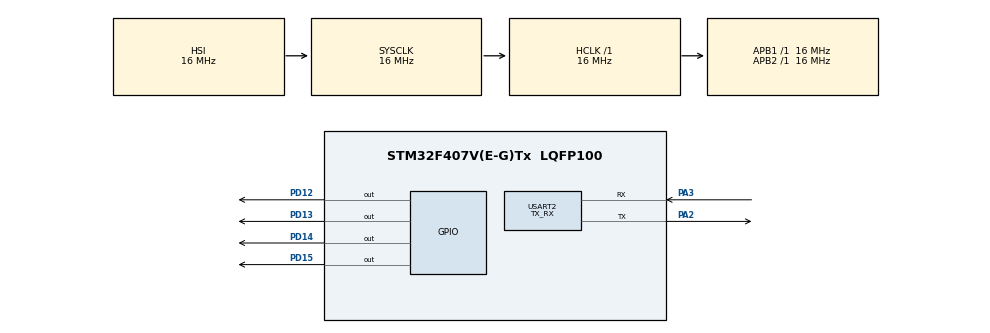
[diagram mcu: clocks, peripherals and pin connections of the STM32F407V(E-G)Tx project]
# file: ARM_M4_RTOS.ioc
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FREERTOS.Tasks01=led_blink,14,128,led_blink_func,Default,NULL,Dynamic,NULL,NULL;usart2_tx,40,128,usart2_tx_func,Default,NULL,Dynamic,NULL,NULL;usart2_rx,41,128,usart2_rx_func,Default,NULL,Dynamic,NULL,NULL
FREERTOS.configUSE_NEWLIB_REENTRANT=1
Mcu.Family=STM32F4
Mcu.Name=STM32F407V(E-G)Tx
Mcu.Package=LQFP100
NVIC.PriorityGroup=NVIC_PRIORITYGROUP_4
NVIC.TIM4_IRQn=true\:15\:0\:false\:false\:true\:false\:false\:true\:true
NVIC.TimeBase=TIM4_IRQn
NVIC.TimeBaseIP=TIM4
PA13.Mode=Serial_Wire
PA13.Signal=SYS_JTMS-SWDIO
PA14.Mode=Serial_Wire
PA14.Signal=SYS_JTCK-SWCLK
PA2.Mode=Asynchronous
PA2.Signal=USART2_TX
PA3.Mode=Asynchronous
PA3.Signal=USART2_RX
PD12.Signal=GPIO_Output
PD13.Signal=GPIO_Output
PD14.Signal=GPIO_Output
PD15.Signal=GPIO_Output
PH0-OSC_IN.Mode=HSE-External-Oscillator
PH0-OSC_IN.Signal=RCC_OSC_IN
PH1-OSC_OUT.Mode=HSE-External-Oscillator
PH1-OSC_OUT.Signal=RCC_OSC_OUT
ProjectManager.HeapSize=0x200
ProjectManager.StackSize=0x400
ProjectManager.TargetToolchain=STM32CubeIDE
RCC.48MHZClocksFreq_Value=96000000
RCC.AHBFreq_Value=16000000
RCC.APB1Freq_Value=16000000
RCC.APB1TimFreq_Value=16000000
RCC.APB2Freq_Value=16000000
RCC.APB2TimFreq_Value=16000000
RCC.CortexFreq_Value=16000000
RCC.HCLKFreq_Value=16000000
RCC.HSE_VALUE=25000000
RCC.HSI_VALUE=16000000
RCC.LSE_VALUE=32768
RCC.PLLM=8
RCC.SYSCLKFreq_VALUE=16000000
RCC.VCOOutputFreq_Value=384000000
USART2.Mode=MODE_TX_RX
USART2.VirtualMode=VM_ASYNC
VP_FREERTOS_VS_CMSIS_V2.Mode=CMSIS_V2
VP_SYS_VS_tim4.Mode=TIM4
board=custom

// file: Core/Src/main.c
/* USER CODE BEGIN Header */
/**
  ******************************************************************************
  * @file           : main.c
  * @brief          : Main program body
  ******************************************************************************
  * @attention
  *
  * Copyright (c) 2026 STMicroelectronics.
  * All rights reserved.
  *
  * This software is licensed under terms that can be found in the LICENSE file
  * in the root directory of this software component.
  * If no LICENSE file comes with this software, it is provided AS-IS.0
  *
  ******************************************************************************
  */
/* USER CODE END Header */
#include "main.h"
#include "cmsis_os.h"
#include "usart.h"
#include "gpio.h"
#include "bl_jump2_appl.h"

void SystemClock_Config(void);
void MX_FREERTOS_Init(void);

/* Flash section non-optimizable defined for allocate the appl key to be validate */
__attribute__((section(".appl_header"))) const appl_header_t appl_header =
{
		.magic_number = 0xAAAACCCC,
		.crc32        = 0x0BB5A287,
		.appl_size    = 21248,
		.ota_flag     = 0,
		.checksum     = 0
};

int main(void)
{

  /* MCU Configuration--------------------------------------------------------*/

  /* Reset of all peripherals, Initializes the Flash interface and the Systick. */
  HAL_Init();

  /* USER CODE BEGIN Init */

  /* Application startup time procedures:
   * Re-fetch of vector tables's application flash region / reset handler entry point
   * Enable interrupts previously disabled by the Bootloader */
   SCB->VTOR = APPL_START_ADDR;
   __enable_irq();

  /* USER CODE END Init */

  /* Configure the system clock */
  SystemClock_Config();

  /* Initialize all configured peripherals */
  MX_GPIO_Init();
  MX_USART2_UART_Init();

  /* Init scheduler */

  osKernelInitialize();  /* Call init function for freertos objects (in cmsis_os2.c) */

  MX_FREERTOS_Init();

  /* Start scheduler */
  osKernelStart();

  /* We should never get here as control is now taken by the scheduler */

  /* Infinite loop */
  while (1)
  {

  }
}

void SystemClock_Config(void)
{
  RCC_OscInitTypeDef RCC_OscInitStruct = {0};
  RCC_ClkInitTypeDef RCC_ClkInitStruct = {0};

  /** Configure the main internal regulator output voltage
  */
  __HAL_RCC_PWR_CLK_ENABLE();
  __HAL_PWR_VOLTAGESCALING_CONFIG(PWR_REGULATOR_VOLTAGE_SCALE1);

  /** Initializes the RCC Oscillators according to the specified parameters
  * in the RCC_OscInitTypeDef structure.
  */
  RCC_OscInitStruct.OscillatorType = RCC_OSCILLATORTYPE_HSI;
  RCC_OscInitStruct.HSIState = RCC_HSI_ON;
  RCC_OscInitStruct.HSICalibrationValue = RCC_HSICALIBRATION_DEFAULT;
  RCC_OscInitStruct.PLL.PLLState = RCC_PLL_NONE;
  if (HAL_RCC_OscConfig(&RCC_OscInitStruct) != HAL_OK)
  {
    Error_Handler();
  }

  /** Initializes the CPU, AHB and APB buses clocks
  */
  RCC_ClkInitStruct.ClockType = RCC_CLOCKTYPE_HCLK|RCC_CLOCKTYPE_SYSCLK
                              |RCC_CLOCKTYPE_PCLK1|RCC_CLOCKTYPE_PCLK2;
  RCC_ClkInitStruct.SYSCLKSource = RCC_SYSCLKSOURCE_HSI;
  RCC_ClkInitStruct.AHBCLKDivider = RCC_SYSCLK_DIV1;
  RCC_ClkInitStruct.APB1CLKDivider = RCC_HCLK_DIV1;
  RCC_ClkInitStruct.APB2CLKDivider = RCC_HCLK_DIV1;

  if (HAL_RCC_ClockConfig(&RCC_ClkInitStruct, FLASH_LATENCY_0) != HAL_OK)
  {
    Error_Handler();
  }
}

void HAL_TIM_PeriodElapsedCallback(TIM_HandleTypeDef *htim)
{
  if (htim->Instance == TIM4)
  {
    HAL_IncTick();
  }
}

void Error_Handler(void)
{
  __disable_irq();
  while (1)
  {
  }
}

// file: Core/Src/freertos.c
/* USER CODE BEGIN Header */
/**
  ******************************************************************************
  * File Name          : freertos.c
  * Description        : Code for freertos applications
  ******************************************************************************
  * @attention
  *
  * Copyright (c) 2026 STMicroelectronics.
  * All rights reserved.
  *
  * This software is licensed under terms that can be found in the LICENSE file
  * in the root directory of this software component.
  * If no LICENSE file comes with this software, it is provided AS-IS.
  *
  ******************************************************************************
  */
/* USER CODE END Header */

#include "FreeRTOS.h"
#include "task.h"
#include "main.h"
#include "cmsis_os.h"

/* USER CODE BEGIN PM */
#define RXBUFFERSIZE 10
/* Exported macro ------------------------------------------------------------*/
#define COUNTOF(__BUFFER__)   (sizeof(__BUFFER__) / sizeof(*(__BUFFER__)))
/* Exported functions ------------------------------------------------------- */
/* Size of Transmission buffer */
#define TXBUFFERSIZE                      (COUNTOF(aTxBuffer) - 1)
/* Size of Reception buffer */

/* USER CODE END PM */

/* USER CODE BEGIN Variables */
uint8_t rtos_tx_buffer[] = {"JUMP to RTOS appl successful...\n"};
uint8_t rtos_rx_buffer[5];
/* USER CODE END Variables */
/* Definitions for led_blink */

osThreadId_t led_blinkHandle;
const osThreadAttr_t led_blink_attributes = {
  .name = "led_blink",
  .stack_size = 128 * 4,
  .priority = (osPriority_t) osPriorityLow6,
};
/* Definitions for usart2_tx */
osThreadId_t usart2_txHandle;
const osThreadAttr_t usart2_tx_attributes = {
  .name = "usart2_tx",
  .stack_size = 128 * 4,
  .priority = (osPriority_t) osPriorityNormal3,
};
/* Definitions for usart2_rx */
osThreadId_t usart2_rxHandle;
const osThreadAttr_t usart2_rx_attributes = {
  .name = "usart2_rx",
  .stack_size = 128 * 4,
  .priority = (osPriority_t) osPriorityHigh,
};

void led_blink_func(void *argument);
void usart2_tx_func(void *argument);
void usart2_rx_func(void *argument);

void MX_FREERTOS_Init(void); /* (MISRA C 2004 rule 8.1) */

void MX_FREERTOS_Init(void) {

  /* Create the thread(s) */
  /* creation of led_blink */
  led_blinkHandle = osThreadNew(led_blink_func, NULL, &led_blink_attributes);

  /* creation of usart2_tx */
  usart2_txHandle = osThreadNew(usart2_tx_func, NULL, &usart2_tx_attributes);

  /* creation of usart2_rx */
  //usart2_rxHandle = osThreadNew(usart2_rx_func, NULL, &usart2_rx_attributes);

}

void led_blink_func(void *argument)
{
  /* USER CODE BEGIN led_blink_func */
  /* Infinite loop */
  for(;;)
  {
	GPIOD->ODR ^= (1 << 15);
    osDelay(100);
  }
  /* USER CODE END led_blink_func */
}

void usart2_tx_func(void *argument)
{
  /* USER CODE BEGIN usart2_tx_func */
  /* Infinite loop */
  for(;;)
  {
	  for(uint8_t j = 0; j < sizeof(rtos_tx_buffer); j++)
	 {
	  	 /* If TXE flag is set, write data byte to DR */
	  	 while(!(USART2->SR & (1 << 6)));
	  	 USART2->DR = (rtos_tx_buffer[j] & 0xFF);
	 }
	 osDelay(1000);
  }
  /* USER CODE END usart2_tx_func */
}

void usart2_rx_func(void *argument)
{
  /* USER CODE BEGIN usart2_rx_func */
  /* Infinite loop */
  for(;;)
  {
	  /* ISSUE: RTOS_BOOT_JUMP_ISSUE
	   * COMMIT: 14019ca.
	   * CAUSE: For being a high priority task, it pre-empts the main() thread flow
	   * execution, therefore, jumps straight away to the for(;;) (line 192) and the scheduler
	   * never starts (osKernelStart();).
	   * Fix in the next commit
	   * for(uint8_t i= 0; i < sizeof(rtos_rx_buffer); i++)
	  {
	  	/* When a character is received, wait until RXNE flag is set, then read data
	  	while(!(USART2->SR & (1 << 5)));
	  	rtos_rx_buffer[i] = USART2->DR; 0xFF & DATA_RX
	  } */
  }
  /* USER CODE END usart2_rx_func */
}
